# S6E2C4xH register map
Vendor: Cypress; File version: 2.1
CPU: CM4 r0p1, little endian, MPU, FPU, 4 interrupt priority bits
Registers are 32-bit, read-write, reset 0x0 unless marked. A register's access mark holds for its fields unless they carry their own. Offsets are from the block's base; [hi:lo] are bit positions; {n}, {i} and the like mark numbered series.

## QPRC0_NF — Quadrature Position/Revolution Counter 0 Noise Filter
Base 0x40026100
Same registers: QPRC1_NF 0x40026110, QPRC2_NF 0x40026120, QPRC3_NF 0x40026130
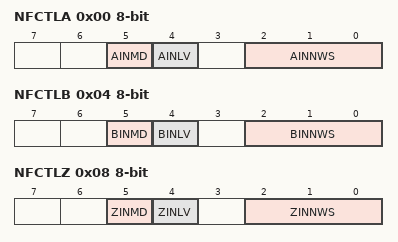
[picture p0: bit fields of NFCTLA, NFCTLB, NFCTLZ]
0x00 NFCTLA 8-bit — AIN Noise Control Register [BHW]
  [5] AINMD — Mask bit
  [4] AINLV — Input invert bit
  [2:0] AINNWS — Noise filter width select bits
0x04 NFCTLB 8-bit — BIN Noise Control Register [BHW]
  [5] BINMD — Mask bit
  [4] BINLV — Input invert bit
  [2:0] BINNWS — Noise filter width select bits
0x08 NFCTLZ 8-bit — ZIN Noise Control Register [BHW]
  [5] ZINMD — Mask bit
  [4] ZINLV — Input invert bit
  [2:0] ZINNWS — Noise filter width select bits

## CRTRIM — CR Trimming Registers
Base 0x4002E000
0x00 MCR_PSR 8-bit reset 0x1 — High-speed CR oscillation Frequency Division Setup Register [BHW]
  [2:0] CSR — High-speed CR oscillation frequency division ratio setting bits
0x04 MCR_FTRM reset 0x1EF — High-speed CR oscillation Frequency Trimming Register [BHW]
  [9:0] TRD — Frequency trimming setup bits
0x08 MCR_TTRM reset 0x10 — High-speed CR oscillation Temperature Trimming Register [BHW]
  [4:0] TRT — Temperature trimming setup bits
0x0C MCR_RLR reset 0x1 — High-Speed CR Oscillation Register Write-Protect Register [W]
  [31:0] TRMLCK — Register write-protect bits

## DAC0 — D/A Converter 0
Base 0x40033000
Same registers: DAC1 0x40033008
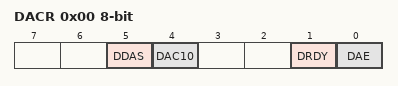
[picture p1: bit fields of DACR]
0x00 DACR 8-bit — D/A Control Register [BHW]
  [5] DDAS — 10-bit mode data allocation selection bit
  [4] DAC10 — 10-bit mode
  [1] DRDY ro — D/A converter operation enable state bit
  [0] DAE — D/A converter operating enable bit
0x04 DADR 16-bit reset not defined — D/A Data Register [HW]
  [11:0] DA — D/A Data Register

## LVD — Low-voltage Detection
Base 0x40035000
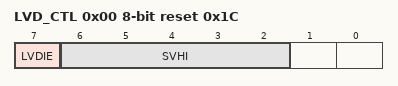
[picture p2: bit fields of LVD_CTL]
0x00 LVD_CTL 8-bit reset 0x1C — Low-voltage Detection Voltage Control Register [BHW]
  [7] LVDIE — Low-voltage detection interrupt enable bit
  [6:2] SVHI — Low-voltage detection interrupt voltage setting bits
0x04 LVD_STR 8-bit ro — Low-voltage Detection Interrupt Factor Register [BHW]
  [7] LVDIR — Low-voltage detection interrupt factor bit
0x08 LVD_CLR 8-bit reset 0x80 — Low-voltage Detection Interrupt Factor Clear Register [BHW]
  [7] LVDCL — Low-voltage detection interrupt factor clear bit
0x0C LVD_RLR reset 0x1 — Low-voltage Detection Voltage Protection Register [W]
  [31:0] LVDLCK — Low-voltage Detection Voltage Control Register protection bits
0x10 LVD_STR2 8-bit ro — Low-voltage Detection Circuit Status Register [BHW]
  [7] LVDIRDY — Low-voltage detection interrupt status flag

## DS — Low Power Consumption Mode
Base 0x40035100
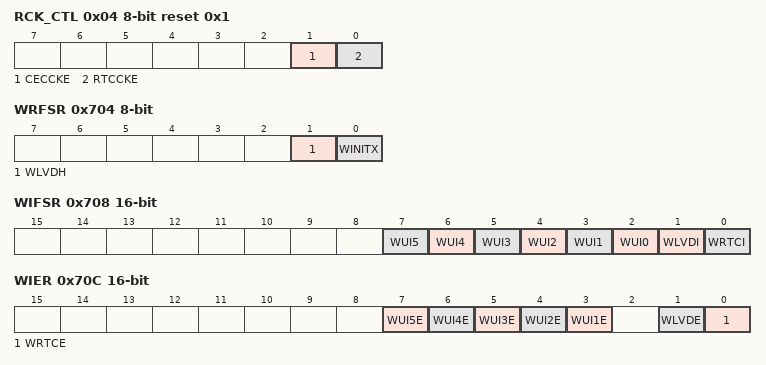
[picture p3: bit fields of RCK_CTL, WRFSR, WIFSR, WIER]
0x04 RCK_CTL 8-bit reset 0x1 — Sub Clock Control Register [BHW]
  [1] CECCKE — CEC clock control bit
  [0] RTCCKE — RTC clock control bit
0x700 PMD_CTL 8-bit — RTC Mode Control Register [BHW]
  [0] RTCE — RTC mode control bit
0x704 WRFSR 8-bit ro — Deep Standby Return Cause Register 1 [BHW]
  [1] WLVDH — Low-voltage detection reset return bit
  [0] WINITX — INITX pin input reset return bit
0x708 WIFSR 16-bit ro — Deep Standby Return Cause Register 2 [BHW]
  [n+2] WUI{n} (n=0..5) — WKUP pin input return bit {n}
  [1] WLVDI — LVD interrupt return bit
  [0] WRTCI — RTC interrupt return bit
0x70C WIER 16-bit — Deep Standby Return Enable Register [BHW]
  [n+2] WUI{n}E (n=1..5) — WKUP pin input return enable bit {n}
  [1] WLVDE — LVD interrupt return enable bit
  [0] WRTCE — RTC interrupt return enable bit
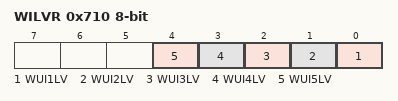
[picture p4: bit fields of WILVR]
0x710 WILVR 8-bit — WKUP Pin Input Level Register [BHW]
  [n-1] WUI{n}LV (n=1..5) — WKUP pin input level select bit {n}
0x714 DSRAMR 8-bit — Deep Standby RAM Retention Register [BHW]
  [1:0] SRAMR — On-chip SRAM retention control bits
{0x7FF+i} BUR{i:02} 8-bit (i=1..16) — Backup Registers from {i} [BHW]

## Notices in the file
Copyright (C) 2013-2016, Cypress Semiconductor Corporation or a
subsidiary of Cypress Semiconductor Corporation.  All rights reserved.
This software, including source code, documentation and related
materials ("Software"), is owned by Cypress Semiconductor Corporation or
one of its subsidiaries ("Cypress") and is protected by and subject to
worldwide patent protection (United States and foreign), United States
copyright laws and international treaty provisions. Therefore, you may use
this Software only as provided in the license agreement accompanying the
software package from which you obtained this Software ("EULA").
If no EULA applies, Cypress hereby grants you a personal, non-exclusive,
non-transferable license to copy, modify, and compile the
Software source code solely for use in connection with Cypress's
integrated circuit products.  Any reproduction, modification, translation,
compilation, or representation of this Software except as specified
above is prohibited without the express written permission of Cypress.
Disclaimer: THIS SOFTWARE IS PROVIDED AS-IS, WITH NO
WARRANTY OF ANY KIND, EXPRESS OR IMPLIED, INCLUDING,
BUT NOT LIMITED TO, NONINFRINGEMENT, IMPLIED
WARRANTIES OF MERCHANTABILITY AND FITNESS FOR A
PARTICULAR PURPOSE. Cypress reserves the right to make
changes to the Software without notice. Cypress does not assume any
liability arising out of the application or use of the Software or any
product or circuit described in the Software. Cypress does not
authorize its products for use in any products where a malfunction or
failure of the Cypress product may reasonably be expected to result in
significant property damage, injury or death ("High Risk Product"). By
including Cypress's product in a High Risk Product, the manufacturer
of such system or application assumes all risk of such use and in doing
so agrees to indemnify Cypress against all liability.
